# RL6678_IP_SVD register map
Vendor: Realtek
Registers are 32-bit, read-write, reset 0x0 unless marked. A register's access mark holds for its fields unless they carry their own. Offsets are from the block's base; [hi:lo] are bit positions; {n}, {i} and the like mark numbered series.

## ED25519_REG
Base 0x400EC000
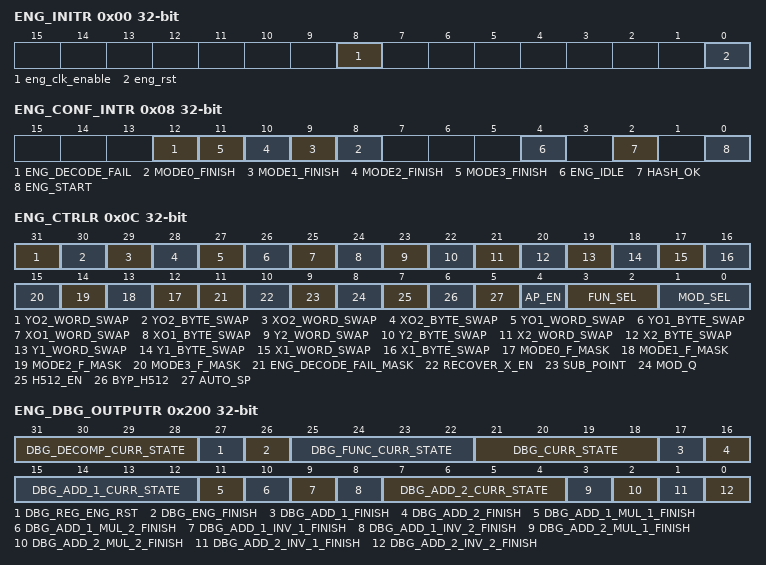
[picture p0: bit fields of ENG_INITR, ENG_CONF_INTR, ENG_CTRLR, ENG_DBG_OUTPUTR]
0x00 ENG_INITR — EdDSA Engine Initial Setting Register
  [8] eng_clk_enable — EdDSA engine clock enable signal.
  [0] eng_rst — EdDSA engine synchronization reset.
0x08 ENG_CONF_INTR — EdDSA Engine Configure Interrupt Register
  [12] ENG_DECODE_FAIL — Engine decode fail interrupt. Put high to clear fail interrupt.
  [n+8] MODE{n}_FINISH (n=0..3) — Engine mode{n} interrupt. Put high to clear mode{n} interrupt.
  [4] ENG_IDLE — When engine is busy, this bit will be put high.
  [2] HASH_OK — When Hash digest input value is ready, put hask_ok to high. Only use this bit in some auto-flow setting. When programer set this bit to 1'b1, it means that hash digest input value is ready, engine can contiune processing next auto-flow step.
  [0] ENG_START — Start for EdDSA function. It's almost for all EdDSA function, except some auto-flow settings. When programer set this bit to 1'b1, it means that input values of the engine mode are ready, so engine can process the mode. Usually it won't be set with HASH_OK.
0x0C ENG_CTRLR — EdDSA Engine Control Register
  [31] YO2_WORD_SWAP — Byte swap 1'b1: |7:0 | 15:8 | 23:16 | 31:24| 1'b0: |31:24 | 23:16 | 15:8 |7:0| Word swap 1'b1: | Word0 | Word1 | Word2 | Word3 | Word4 | Word5 | Word6 | Word7 | 1'b0: | Word7 | Word6 | Word5 | Word4 | Word3 | Word2 | Word1 | Word0 |
  [30] YO2_BYTE_SWAP — merged
  [29] XO2_WORD_SWAP — merged
  [28] XO2_BYTE_SWAP — merged
  [27] YO1_WORD_SWAP — merged
  [26] YO1_BYTE_SWAP — merged
  [25] XO1_WORD_SWAP — merged
  [24] XO1_BYTE_SWAP — merged
  [23] Y2_WORD_SWAP — merged
  [22] Y2_BYTE_SWAP — merged
  [21] X2_WORD_SWAP — merged
  [20] X2_BYTE_SWAP — merged
  [19] Y1_WORD_SWAP — merged
  [18] Y1_BYTE_SWAP — merged
  [17] X1_WORD_SWAP — merged
  [16] X1_BYTE_SWAP — merged
  [n+12] MODE{n}_F_MASK (n=0..3) — Mask mode{n} finish interrupt
  [11] ENG_DECODE_FAIL_MASK — Mask decoding fail interrupt
  [10] RECOVER_X_EN — Reocver (decode) point enable contrl. When this bit is set to 1'b1, it means that enable decoding mode.
  [9] SUB_POINT — Point subtraction enable control in mode2.
  [8] MOD_Q — Select modular1 or 2 for Hash mod. Modular1: hash[511:0] modular (2^255 - 19) Modular2: hash[511:0] modular (2^252+ 27742317777372353535851937790883648493)
  [7] H512_EN — SHA512 hash enable control.
  [6] BYP_H512 — SHA512 hash bypass mode control.
  [5] AUTO_SP — Auto-flow step enable control. Basically, it is used to open one pass flow in mode0/mode1 flow. It won't be set in mode2/mode3.
  [4] AP_EN — Add point enable control. It is only used in mode3.
  [3:2] FUN_SEL — EdDSA Basic Function selection 2'd0: * Decode point * Add point * Sub mod It depends on ECOVER_X_EN and AP_EN. 2'd1: Div mode 2'd2: Add mode 2'd3: * Mult mod * Hash mod #modular1 * Hash mod #modular2. It depends on H512_EN and MOD_Q.
  [1:0] MOD_SEL — EdDSA mode selection 2'd0: Mode0 2'd1: Mode1 2'd2: Mode2 2'd3: Mode3
{0x10+4i} ENG_X1_P{i} (i=0..7) — EdDSA Engine X1 Point Register {i}
  [31:0] ENG_X1_P{i} — X1 value[31:0] of an input point.
{0x30+4i} ENG_Y1_P{i} (i=0..7) — EdDSA Engine Y1 Point Register {i}
  [31:0] ENG_Y1_P{i} — Y1 value[31:0] of an input point.
{0x50+4i} ENG_X2_P{i} (i=0..7) — EdDSA Engine X2 Point Register {i}
  [31:0] ENG_X2_P{i} — X2 value[31:0] of an input point.
{0x70+4i} ENG_Y2_P{i} (i=0..7) — EdDSA Engine Y2 Point Register {i}
  [31:0] ENG_Y2_P{i} — Y2 value[31:0] of an input point.
{0x90+4i} ENG_XO1_P{i} (i=0..7) — EdDSA Engine X1 Point Register {i}
  [31:0] ENG_XO1_P{i} — X1 value[31:0] of an output point.
{0xB0+4i} ENG_YO1_P{i} (i=0..7) — EdDSA Engine Y1 Point Register {i}
  [31:0] ENG_YO1_P{i} — Y1 value[31:0] of an input point.
{0xD0+4i} ENG_XO2_P{i} (i=0..7) — EdDSA Engine X2 Point Register {i}
  [31:0] ENG_XO2_P{i} — X2 value[31:0] of an output point.
{0xF0+4i} ENG_YO2_P{i} ro (i=0..7) — EdDSA Engine Y2 Point Register {i}
  [31:0] ENG_YO2_P{i} — Y2 value[31:0] of an output point.
0x200 ENG_DBG_OUTPUTR ro — EdDSA Engine Debug Output Register
  [31:28] DBG_DECOMP_CURR_STATE — FSM signal in decoding module
  [27] DBG_REG_ENG_RST — Reset signal in top module
  [26] DBG_ENG_FINISH — FSM signal in top module
  [25:22] DBG_FUNC_CURR_STATE — Function FSM signal in top module
  [21:18] DBG_CURR_STATE — FSM signal in top module
  [17] DBG_ADD_1_FINISH — Finish signal in add_1 module
  [16] DBG_ADD_2_FINISH — Finish signal in add_2 module
  [15:12] DBG_ADD_1_CURR_STATE — FSM signal in add_1module
  [11] DBG_ADD_1_MUL_1_FINISH — mul and inv module finish signal in add_1 module
  [10] DBG_ADD_1_MUL_2_FINISH — merged
  [9] DBG_ADD_1_INV_1_FINISH — merged
  [8] DBG_ADD_1_INV_2_FINISH — merged
  [7:4] DBG_ADD_2_CURR_STATE — FSM signal in add_2 module
  [3] DBG_ADD_2_MUL_1_FINISH — mul and inv module finish signal in add_2 module
  [2] DBG_ADD_2_MUL_2_FINISH — merged
  [1] DBG_ADD_2_INV_1_FINISH — merged
  [0] DBG_ADD_2_INV_2_FINISH — merged
